BO_ 717 ASCM_2CD: 5 K124_ASCM

BO_ 869 ASCM_365: 4 K124_ASCM

BO_ 1034 ASCM_40A: 7 K124_ASCM

BO_ 1296 ASCM_510: 4 K124_ASCM

BO_ 1930 ASCM_78A: 7 K124_ASCM

BO_ 190 ECMAcceleratorPos: 6 K20_ECM
 SG_ BrakePedalPos : 15|8@0+ (1,0) [0|0] "sticky"  NEO
 SG_ GasPedalAndAcc : 23|8@0+ (1,0) [0|0] ""  NEO

BO_ 201 ECMEngineStatus: 8 K20_ECM
 SG_ EngineTPS : 39|8@0+ (0.392156863,0) [0|100.000000065] "%"  NEO
 SG_ EngineRPM : 15|16@0+ (0.25,0) [0|0] "RPM"  NEO

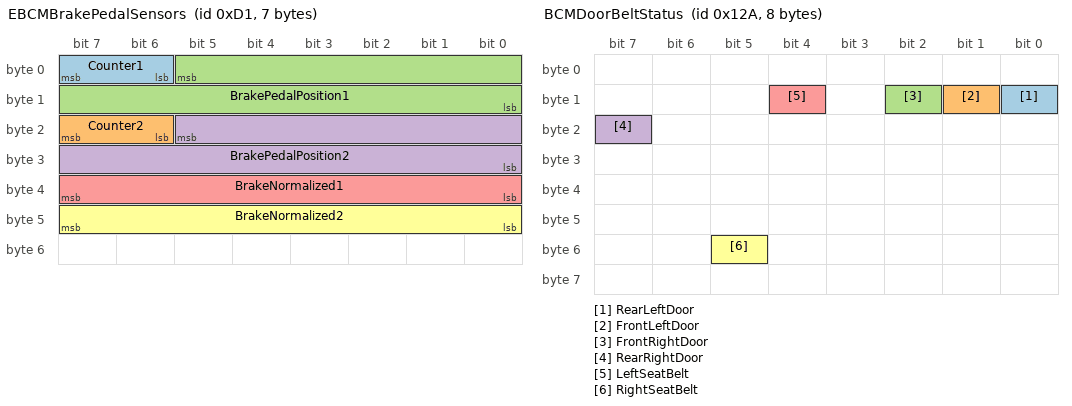
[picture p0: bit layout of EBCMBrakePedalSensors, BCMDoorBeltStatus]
BO_ 209 EBCMBrakePedalSensors: 7 K17_EBCM
 SG_ Counter1 : 7|2@0+ (1,0) [0|3] "" XXX
 SG_ Counter2 : 23|2@0+ (1,0) [0|3] "" XXX
 SG_ BrakePedalPosition1 : 5|14@0+ (1,0) [0|16383] "" XXX
 SG_ BrakePedalPosition2 : 21|14@0- (-1,0) [0|16383] "" XXX
 SG_ BrakeNormalized1 : 39|8@0+ (1,0) [0|255] "" XXX
 SG_ BrakeNormalized2 : 47|8@0- (-1,0) [0|255] "" XXX

BO_ 241 EBCMBrakePedalPosition: 6 K17_EBCM
 SG_ BrakePedalPosition : 15|8@0+ (1,0) [0|255] ""  NEO

BO_ 298 BCMDoorBeltStatus: 8 K9_BCM
 SG_ RearLeftDoor : 8|1@0+ (1,0) [0|0] ""  NEO
 SG_ FrontLeftDoor : 9|1@0+ (1,0) [0|0] ""  NEO
 SG_ FrontRightDoor : 10|1@0+ (1,0) [0|0] ""  NEO
 SG_ RearRightDoor : 23|1@0+ (1,0) [0|0] ""  NEO
 SG_ LeftSeatBelt : 12|1@0+ (1,0) [0|0] ""  NEO
 SG_ RightSeatBelt : 53|1@0+ (1,0) [0|0] ""  NEO

BO_ 309 ECMPRDNL: 8 K20_ECM
 SG_ PRNDL : 2|3@0+ (1,0) [0|0] ""  NEO

BO_ 320 BCMTurnSignals: 3 K9_BCM
 SG_ TurnSignals : 19|2@0+ (1,0) [0|0] ""  NEO

BO_ 336 ASCMLKASStatus: 1 NEO
 SG_ Available : 7|1@0+ (1,0) [0|0] ""  NEO

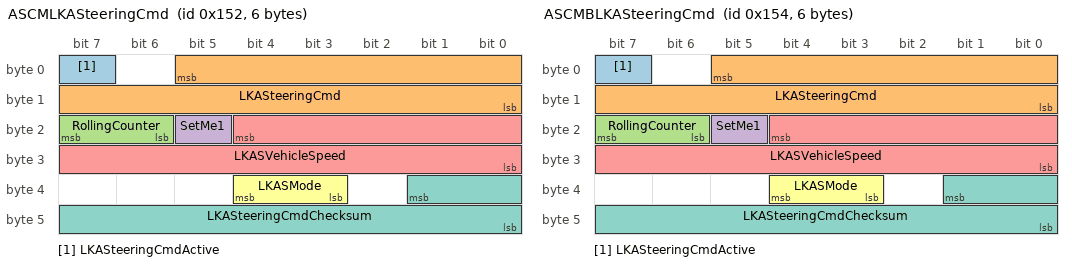
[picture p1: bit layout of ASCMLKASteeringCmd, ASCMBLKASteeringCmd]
BO_ 338 ASCMLKASteeringCmd: 6 NEO
 SG_ LKASteeringCmdActive : 7|1@0+ (1,0) [0|0] ""  NEO
 SG_ LKASteeringCmd : 5|14@0- (1,0) [0|0] ""  NEO
 SG_ RollingCounter : 23|2@0+ (1,0) [0|0] ""  NEO
 SG_ SetMe1 : 21|1@0+ (1,0) [0|0] ""  NEO
 SG_ LKASVehicleSpeed : 20|13@0+ (0.22,0) [0|0] "kph" NEO
 SG_ LKASMode : 36|2@0+ (1,0) [0|0] ""  NEO
 SG_ LKASteeringCmdChecksum : 33|10@0+ (1,0) [0|0] ""  NEO

BO_ 340 ASCMBLKASteeringCmd: 6 NEO
 SG_ LKASteeringCmdActive : 7|1@0+ (1,0) [0|0] ""  NEO
 SG_ LKASteeringCmd : 5|14@0- (1,0) [0|0] ""  NEO
 SG_ RollingCounter : 23|2@0+ (1,0) [0|0] ""  NEO
 SG_ SetMe1 : 21|1@0+ (1,0) [0|0] ""  NEO
 SG_ LKASVehicleSpeed : 20|13@0+ (0.22,0) [0|0] "kph" NEO
 SG_ LKASMode : 36|2@0+ (1,0) [0|0] ""  NEO
 SG_ LKASteeringCmdChecksum : 33|10@0+ (1,0) [0|0] ""  NEO

BO_ 381 MSG_17D: 8 K20_ECM
 SG_ MSG17D_AccPower : 35|12@0- (1,0) [0|0] ""  NEO

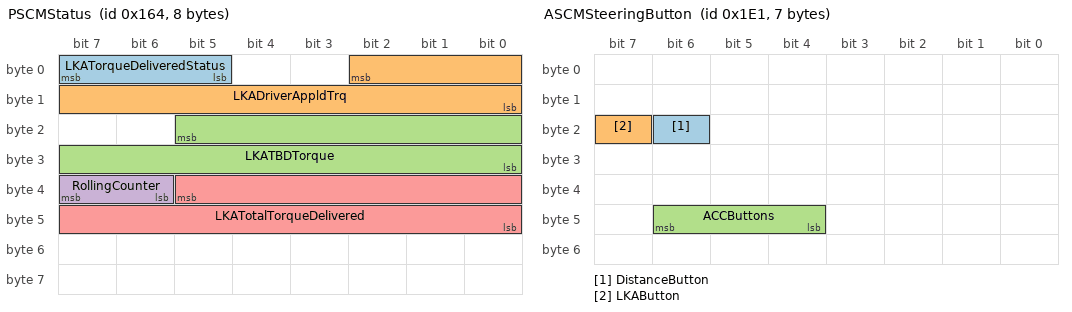
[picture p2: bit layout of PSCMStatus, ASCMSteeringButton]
BO_ 356 PSCMStatus: 8 K43_PSCM
 SG_ LKATorqueDeliveredStatus : 7|3@0+ (1,0) [0|7] ""  NEO
 SG_ LKADriverAppldTrq : 2|11@0- (0.01,0) [-10.24|10.23] "Nm"  NEO
 SG_ LKATBDTorque : 21|14@0- (-0.005,0) [-10.24|10.23] "Nm"  NEO
 SG_ RollingCounter : 39|2@0+ (1,0) [0|0] ""  NEO
 SG_ LKATotalTorqueDelivered : 37|14@0- (0.01,0) [-10.24|10.23] "Nm"  NEO

BO_ 417 AcceleratorPedal: 7 XXX
 SG_ AcceleratorPedal : 55|8@0+ (1,0) [0|0] ""  NEO

BO_ 451 GasAndAcc: 8 XXX
 SG_ GasPedalAndAcc2 : 55|8@0+ (1,0) [0|0] ""  NEO

BO_ 452 AcceleratorPedal2: 8 XXX
 SG_ AcceleratorPedal2 : 47|8@0+ (1,0) [0|0] ""  NEO

BO_ 481 ASCMSteeringButton: 7 K124_ASCM
 SG_ DistanceButton : 22|1@0+ (1,0) [0|0] ""  NEO
 SG_ LKAButton : 23|1@0+ (1,0) [0|0] ""  NEO
 SG_ ACCButtons : 46|3@0+ (1,0) [0|0] ""  NEO

BO_ 485 PSCMSteeringAngle: 8 K43_PSCM
 SG_ SteeringWheelAngle : 15|16@0- (0.0625,0) [-2047|2047] "deg"  NEO
 SG_ SteeringWheelRate : 27|12@0- (1,0) [-2047|2047] "deg/s"  NEO

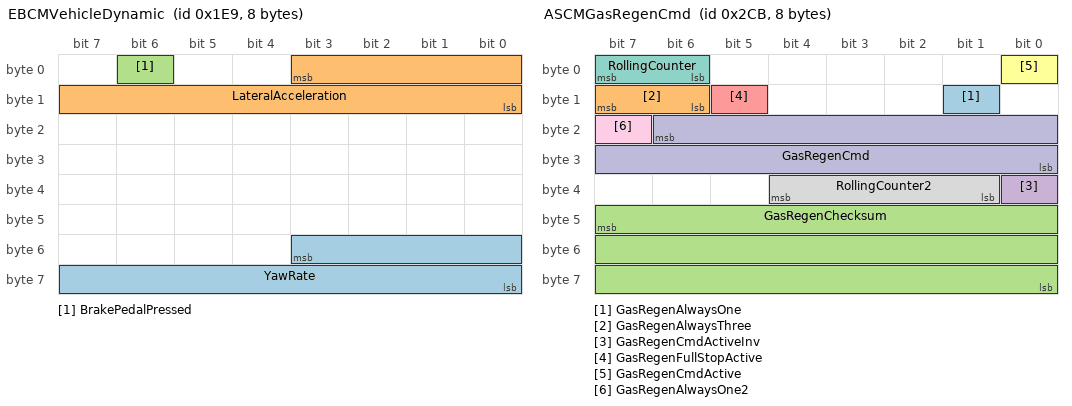
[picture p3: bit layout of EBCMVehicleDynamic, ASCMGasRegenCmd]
BO_ 489 EBCMVehicleDynamic: 8 K17_EBCM
 SG_ YawRate : 51|12@0- (0.0625,0) [-2047|2047] "grad/s"  NEO
 SG_ LateralAcceleration : 3|12@0- (0.0161,0) [-2047|2047] "m/s2"  NEO
 SG_ BrakePedalPressed : 6|1@0+ (1,0) [0|0] ""  NEO

BO_ 711 BECMBatteryVoltageCurrent: 6 K17_EBCM
 SG_ HVBatteryVoltage : 31|12@0+ (0.125,0) [0|511.875] "V"  NEO
 SG_ HVBatteryCurrent : 12|13@0- (0.15,0) [-614.4|614.25] "A"  NEO

BO_ 715 ASCMGasRegenCmd: 8 K124_ASCM
 SG_ GasRegenAlwaysOne : 9|1@0+ (1,1) [1|1] ""  NEO
 SG_ GasRegenAlwaysThree : 15|2@0+ (1,1) [1|1] ""  NEO
 SG_ GasRegenChecksum : 47|24@0+ (1,0) [0|0] ""  NEO
 SG_ GasRegenCmdActiveInv : 32|1@0+ (1,0) [0|0] ""  NEO
 SG_ GasRegenFullStopActive : 13|1@0+ (1,0) [0|0] ""  NEO
 SG_ GasRegenCmdActive : 0|1@0+ (1,0) [0|0] ""  NEO
 SG_ RollingCounter : 7|2@0+ (1,0) [0|0] ""  NEO
 SG_ RollingCounter2 : 36|4@0+ (1,0) [0|0] ""  NEO
 SG_ GasRegenAlwaysOne2 : 23|1@0+ (1,0) [0|1] ""  NEO
 SG_ GasRegenCmd : 22|15@0+ (1,0) [0|0] ""  NEO

BO_ 810 TCICOnStarGPSPosition: 8 K73_TCIC
 SG_ GPSLongitude : 39|32@0+ (1,-2147483648) [0|0] "milliarcsecond"  NEO
 SG_ GPSLatitude : 7|32@0+ (1,0) [0|0] "milliarcsecond"  NEO

BO_ 840 EBCMWheelSpdFront: 4 K17_EBCM
 SG_ FLWheelSpd : 7|16@0+ (0.0311,0) [0|255] "km/h"  NEO
 SG_ FRWheelSpd : 23|16@0+ (0.0311,0) [0|255] "km/h"  NEO

BO_ 842 EBCMWheelSpdRear: 4 K17_EBCM
 SG_ RLWheelSpd : 7|16@0+ (0.0311,0) [0|255] "km/h"  NEO
 SG_ RRWheelSpd : 23|16@0+ (0.0311,0) [0|255] "km/h"  NEO

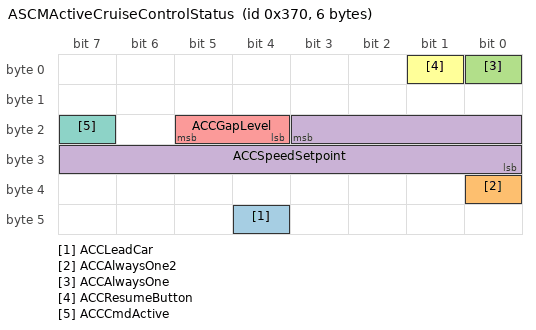
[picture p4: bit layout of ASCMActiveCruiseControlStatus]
BO_ 880 ASCMActiveCruiseControlStatus: 6 K124_ASCM
 SG_ ACCLeadCar : 44|1@0+ (1,0) [0|0] "" Vector__XXX
 SG_ ACCAlwaysOne2 : 32|1@0+ (1,0) [0|0] "" Vector__XXX
 SG_ ACCAlwaysOne : 0|1@0+ (1,0) [0|0] "" Vector__XXX
 SG_ ACCSpeedSetpoint : 19|12@0+ (0.0625,0) [0|255.9375] "km/h"  NEO
 SG_ ACCGapLevel : 21|2@0+ (1,0) [0|0] ""  NEO
 SG_ ACCResumeButton : 1|1@0+ (1,0) [0|0] ""  NEO
 SG_ ACCCmdActive : 23|1@0+ (1,0) [0|0] ""  NEO

BO_ 1001 ECMVehicleSpeed: 8 K20_ECM
 SG_ VehicleSpeed : 7|16@0+ (0.01,0) [0|0] "mph"  NEO

BO_ 1033 ASCMKeepAlive: 7 NEO
 SG_ ASCMKeepAliveAllZero : 7|56@0+ (1,0) [0|0] ""  NEO

BO_ 1217 ECMEngineCoolantTemp: 8 K20_ECM
 SG_ EngineCoolantTemp : 23|8@0+ (1,-40) [0|0] "C"  NEO

BO_ 1249 VIN_Part2: 8 K20_ECM
 SG_ VINPart2 : 7|64@0+ (1,0) [0|0] ""  NEO

BO_ 1300 VIN_Part1: 8 K20_ECM
 SG_ VINPart1 : 7|64@0+ (1,0) [0|0] ""  NEO

BO_ 1912 PSCM_778: 8 K43_PSCM

BO_TX_BU_ 338 : K124_ASCM,NEO;
BO_TX_BU_ 880 : NEO,K124_ASCM;
BO_TX_BU_ 1033 : K124_ASCM,NEO;
BO_TX_BU_ 715 : NEO,K124_ASCM;

BU_: K16_BECM K73_TCIC K9_BCM K43_PSCM K17_EBCM K20_ECM K114B_HPCM NEO K124_ASCM EPB
VAL_TABLE_ TurnSignals 2 "Right Turn" 1 "Left Turn" 0 "None" ;
VAL_TABLE_ Intellibeam 1 "Active" 0 "Inactive" ;
VAL_TABLE_ HighBeamsActive 1 "Active" 0 "Inactive" ;
VAL_TABLE_ HighBeamsTemporary 1 "Active" 0 "Inactive" ;
VAL_TABLE_ ACCLeadCar 1 "Present" 0 "Not Present" ;
VAL_TABLE_ ACCCmdActive 1 "Active" 0 "Inactive" ;
VAL_TABLE_ BrakePedalPressed 1 "Pressed" 0 "Depressed" ;
VAL_TABLE_ DistanceButton 1 "Active" 0 "Inactive" ;
VAL_TABLE_ LKAButton 1 "Active" 0 "Inactive" ;
VAL_TABLE_ ACCButtons 6 "Cancel" 5 "Main" 3 "Set" 2 "Resume" 1 "None" ;
VAL_TABLE_ DriveModeButton 1 "Active" 0 "Inactive" ;
VAL_TABLE_ PRNDL 3 "Reverse" 2 "Drive" 1 "Neutral" 0 "Park" ;
VAL_TABLE_ ESPButton 1 "Active" 0 "Inactive" ;
VAL_TABLE_ DoorStatus 1 "Opened" 0 "Closed" ;
VAL_TABLE_ SeatBeltStatus 1 "Latched" 0 "Unlatched" ;
VAL_TABLE_ LKASteeringCmdActive 1 "Active" 0 "Inactive" ;
VAL_TABLE_ ACCGapLevel 3 "Far" 2 "Med" 1 "Near" 0 "Inactive" ;
VAL_TABLE_ GasRegenCmdActiveInv 1 "Inactive" 0 "Active" ;
VAL_TABLE_ GasRegenCmdActive 1 "Active" 0 "Inactive" ;
VAL_TABLE_ LKATorqueDeliveredStatus 3 "Failed" 2 "Temp. Limited" 1 "Active" 0 "Inactive" ;
VAL_TABLE_ HandsOffSWDetectionStatus 1 "Hands On" 0 "Hands Off" ;
VAL_TABLE_ HandsOffSWDetectionMode 2 "Failed" 1 "Enabled" 0 "Disabled" ;

CM_ BU_ K182_PACM "Parking Assist Control Module";
CM_ BU_ K43_PSCM "Power Steering Control Module";
CM_ BU_ K17_EBCM "Electronic Brake Control Module";
CM_ BU_ NEO "Comma NEO";
CM_ BU_ K124_ASCM "Active Safety Control Module";
BA_DEF_  "UseGMParameterIDs" INT 0 0;
BA_DEF_  "ProtocolType" STRING ;
BA_DEF_  "BusType" STRING ;
BA_DEF_DEF_  "UseGMParameterIDs" 1;
BA_DEF_DEF_  "ProtocolType" "GMLAN";
BA_DEF_DEF_  "BusType" "";
BA_ "UseGMParameterIDs" 0;
BA_ "BusType" "CAN";

VAL_ 53 GEAR 0 "P" 5 "D" 6 "N" 7 "R" ;
VAL_ 64 GEAR 0 "P" 5 "D" 6 "N" 7 "R" ;
VAL_ 69 GEAR 0 "P" 5 "D" 6 "N" 7 "R" ;
VAL_ 112 GEAR 0 "P" 5 "D" 6 "N" 7 "R" ;
VAL_ 80 LKA_ICON 0 "hidden" 1 "grey" 2 "green" 3 "flashing green" ;
VAL_ 80 LKA_MODE 1 "warning only" 2 "assist" 6 "off" ;
VAL_ 96 TRACTION_AND_STABILITY_CONTROL 0 "On" 5 "Limited" 1 "Off";
VAL_ 234 LKA_FAULT 0 "ok" 1 "lka fault" ;
VAL_ 272 LKA_ICON 0 "hidden" 1 "grey" 2 "green" 3 "flashing green" ;
VAL_ 272 LKA_MODE 1 "warning only" 2 "assist" 6 "off" ;
VAL_ 298 LKA_ICON 0 "hidden" 1 "grey" 2 "green" 3 "flashing green" ;
VAL_ 298 LKA_MODE 1 "warning only" 2 "assist" 6 "off" ;
VAL_ 304 PARK_BUTTON 1 "Pressed" 2 "Not Pressed";
VAL_ 304 KNOB_POSITION 1 "R" 2 "N (on R side)" 3 "Centered" 4 "N (on D side)" 5 "D";
VAL_ 304 GEAR 1 "P" 2 "R" 3 "N" 4 "D" ;
VAL_ 352 AEB_SETTING 1 "off" 2 "warning only" 3 "active assist" ;
VAL_ 362 BLINKER_CONTROL 1 "hazards" 2 "hazards button backlight" 3 "left blinkers" 4 "right blinkers";
VAL_ 373 ACCEnable 0 "SCC ready" 1 "SCC temp fault" 2 "SCC permanent fault" 3 "SCC permanent fault, communication issue";
VAL_ 416 ACCMode 0 "off" 1 "enabled" 2 "driver_override" 3 "off_maybe_fault" 4 "cancelled" ;
VAL_ 426 CRUISE_BUTTONS 0 "none" 1 "res_accel" 2 "set_decel" 3 "gap_distance" 4 "pause_resume" ;
VAL_ 463 CRUISE_BUTTONS 0 "none" 1 "res_accel" 2 "set_decel" 3 "gap_distance" 4 "pause_resume" ;
VAL_ 463 RIGHT_PADDLE 0 "Not Pulled" 1 "Pulled";
VAL_ 463 LEFT_PADDLE 0 "Not Pulled" 1 "Pulled";
VAL_ 676 LEFT_LANE_LINE 0 "Not Detected" 1 "Low Confidence" 2 "Medium Confidence" 3 "High Confidence";
VAL_ 676 RIGHT_LANE_LINE 0 "Not Detected" 1 "Low Confidence" 2 "Medium Confidence" 3 "High Confidence";
VAL_ 736 MSLA_STATUS 0 "disabled" 1 "active" 2 "paused";
VAL_ 866 LEFT_LANE_LINE 0 "Not Detected" 1 "Low Confidence" 2 "Medium Confidence" 3 "High Confidence";
VAL_ 866 RIGHT_LANE_LINE 0 "Not Detected" 1 "Low Confidence" 2 "Medium Confidence" 3 "High Confidence";
VAL_ 1041 DRIVER_DOOR 0 "Closed" 1 "Opened";
VAL_ 1041 PASSENGER_DOOR 0 "Closed" 1 "Opened";
VAL_ 1041 DRIVER_REAR_DOOR 0 "Closed" 1 "Opened";
VAL_ 1041 PASSENGER_REAR_DOOR 0 "Closed" 1 "Opened";
VAL_ 1041 DRIVER_SEATBELT 0 "Unlatched" 1 "Latched";
VAL_ 1041 PASSENGER_SEATBELT 0 "Unlatched" 1 "Latched";
VAL_ 1144 DRIVE_MODE2 3 "Set Sport" 1 "Set Normal" 2 "Set Eco";
